# STM32U5Fx register map
File version: 1.0
CPU: CM33 r0p1, little endian, MPU, FPU, 4 interrupt priority bits
Registers are 32-bit, read-write, reset 0x0 unless marked. A register's access mark holds for its fields unless they carry their own. Offsets are from the block's base; [hi:lo] are bit positions; {n}, {i} and the like mark numbered series; 'fields as' and 'values as' point back to an identical list.

## OCTOSPIM — OCTOSPI I/O manager
Base 0x420C4000
Same registers: SEC_OCTOSPIM 0x520C4000
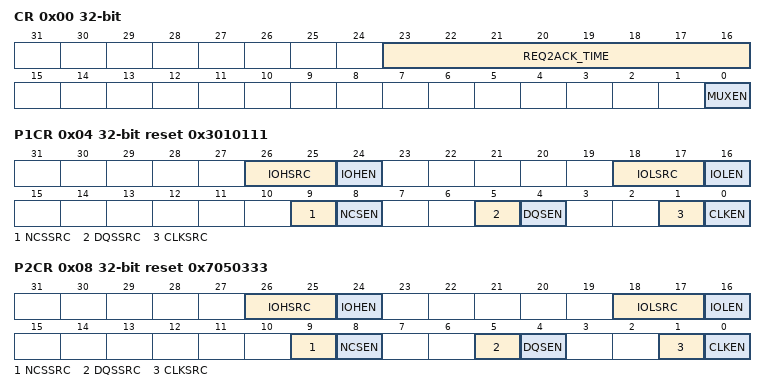
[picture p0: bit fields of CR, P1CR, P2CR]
0x00 CR — control register
  [23:16] REQ2ACK_TIME — REQ to ACK time
  [0] MUXEN — Multiplexed mode enable
0x04 P1CR reset 0x3010111 — OCTOSPI I/O manager Port 1 configuration register
  [26:25] IOHSRC — IOHSR
  [24] IOHEN
  [18:17] IOLSRC
  [16] IOLEN
  [9] NCSSRC
  [8] NCSEN
  [5] DQSSRC
  [4] DQSEN
  [1] CLKSRC
  [0] CLKEN
0x08 P2CR reset 0x7050333 — OCTOSPI I/O manager Port 2 configuration register
  fields as P1CR

## PSSI
Base 0x4202C400
Same registers: SEC_PSSI 0x5202C400
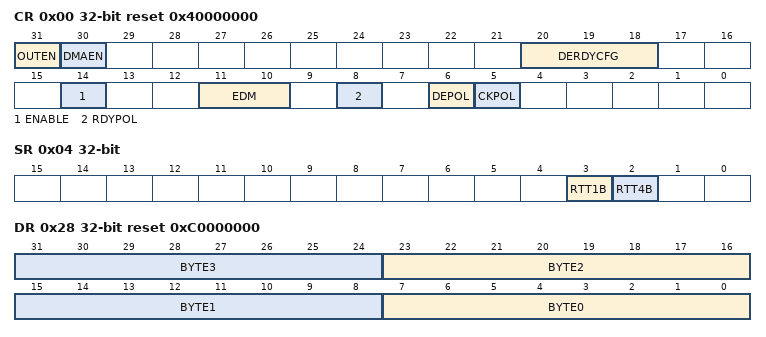
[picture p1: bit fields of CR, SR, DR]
0x00 CR reset 0x40000000 — PSSI control register
  [31] OUTEN — Data direction selection bit
  [30] DMAEN — DMA enable bit
  [20:18] DERDYCFG — Data enable and ready configuration When the PSSI_RDY function is mapped to the PSSI_DE pin (settings 101 or 111), it is still the RDYPOL bit which determines its polarity. Similarly, when the PSSI_DE function is mapped to the PSSI_RDY pin (settings 110 or 111), it is still the DEPOL bit which determines its polarity.
  [14] ENABLE — PSSI enable The contents of the FIFO are flushed when ENABLE is cleared to 0. Note: When ENABLE=1, the content of PSSI_CR must not be changed, except for the ENABLE bit itself. All configuration bits can change as soon as ENABLE changes from 0 to 1. The DMA controller and all PSSI configuration registers must be programmed correctly before setting the ENABLE bit to 1. The ENABLE bit and the DCMI ENABLE bit (bit 15 of DCMI_CR) must not be set to 1 at the same time.
  [11:10] EDM — Extended data mode
  [8] RDYPOL — Ready (PSSI_RDY) polarity This bit indicates the level on the PSSI_RDY pin when the data are not valid on the parallel interface.
  [6] DEPOL — Data enable (PSSI_DE) polarity This bit indicates the level on the PSSI_DE pin when the data are not valid on the parallel interface.
  [5] CKPOL — Parallel data clock polarity This bit configures the capture edge of the parallel clock or the edge used for driving outputs, depending on OUTEN.
0x04 SR ro — PSSI status register
  [3] RTT1B, [2] RTT4B
0x08 RIS ro — PSSI raw interrupt status register
  [1] OVR_RIS
0x0C IER — PSSI interrupt enable register
  [1] OVR_IE
0x10 MIS ro — PSSI masked interrupt status register
  [1] OVR_MIS
0x14 ICR wo — PSSI interrupt clear register
  [1] OVR_ISC
0x28 DR reset 0xC0000000 — PSSI data register
  [8n+7:8n] BYTE{n} (n=0..3) — Data byte {n}

## RNG — Random number generator
Base 0x420C0800
Same registers: SEC_RNG 0x520C0800
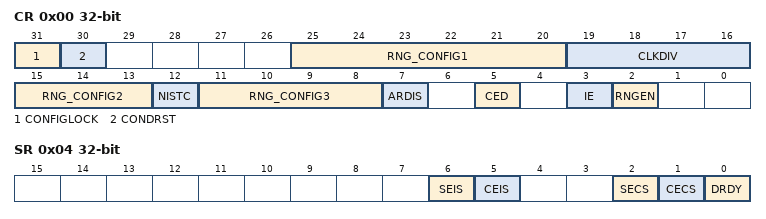
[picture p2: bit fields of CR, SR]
0x00 CR — control register
  [31] CONFIGLOCK — RNG Config Lock
  [30] CONDRST — Conditioning soft reset
  [25:20] RNG_CONFIG1 — RNG configuration 1
  [19:16] CLKDIV — Clock divider factor
  [15:13] RNG_CONFIG2 — RNG configuration 2
  [12] NISTC — Non NIST compliant
  [11:8] RNG_CONFIG3 — RNG configuration 3
  [7] ARDIS — Auto reset disable
  [5] CED — Clock error detection
  [3] IE — Interrupt Enable
  [2] RNGEN — True random number generator enable
0x04 SR access per field — status register
  [6] SEIS rw — Seed error interrupt status
  [5] CEIS rw — Clock error interrupt status
  [2] SECS ro — Seed error current status
  [1] CECS ro — Clock error current status
  [0] DRDY ro — Data ready
0x08 DR ro — data register
  [31:0] RNDATA — Random data
0x10 HTCR reset 0x6274 — health test control register
  [31:0] HTCFG — health test configuration

## SPI1 — Serial peripheral interface
Base 0x40013000
Same registers: SPI2 0x40003800, SPI3 0x46002000, SEC_SPI2 0x50003800, SEC_SPI1 0x50013000, SEC_SPI3 0x56002000
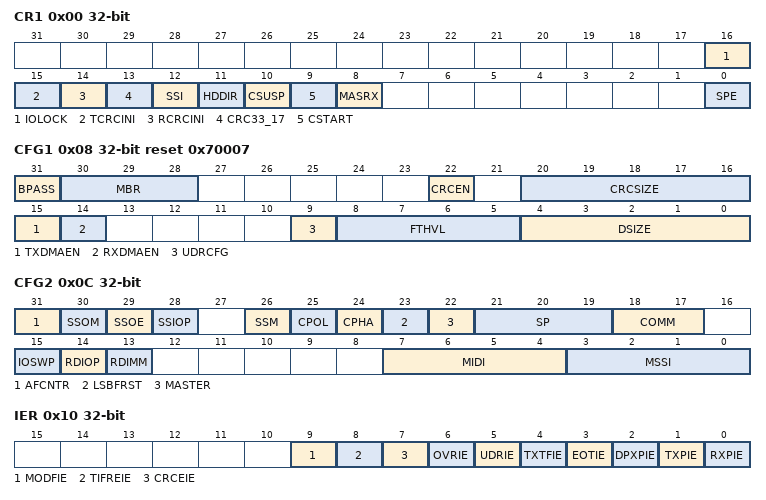
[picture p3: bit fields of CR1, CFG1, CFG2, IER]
0x00 CR1 access per field — control register 1
  [16] IOLOCK rw, [15] TCRCINI rw, [14] RCRCINI rw, [13] CRC33_17 rw, [12] SSI rw, [11] HDDIR rw, [10] CSUSP wo, [9] CSTART rw, [8] MASRX rw, [0] SPE rw
0x04 CR2 — control register 2
  [15:0] TSIZE
0x08 CFG1 reset 0x70007 — configuration register 1
  [31] BPASS
  [30:28] MBR — Master baud rate
  [22] CRCEN — Hardware CRC computation enable
  [20:16] CRCSIZE — Length of CRC frame to be transacted and compared
  [15] TXDMAEN — Tx DMA stream enable
  [14] RXDMAEN — Rx DMA stream enable
  [9] UDRCFG — Behavior of slave transmitter at underrun condition
  [8:5] FTHVL — threshold level
  [4:0] DSIZE — Number of bits in at single SPI data frame
0x0C CFG2 — configuration register 2
  [31] AFCNTR — Alternate function GPIOs control
  [30] SSOM — SS output management in master mode
  [29] SSOE — SS output enable
  [28] SSIOP — SS input/output polarity
  [26] SSM — Software management of SS signal input
  [25] CPOL — Clock polarity
  [24] CPHA — Clock phase
  [23] LSBFRST — Data frame format
  [22] MASTER — SPI Master
  [21:19] SP — Serial Protocol
  [18:17] COMM — SPI Communication Mode
  [15] IOSWP — Swap functionality of MISO and MOSI pins
  [14] RDIOP
  [13] RDIMM
  [7:4] MIDI — Master Inter-Data Idleness
  [3:0] MSSI — Master SS Idleness
0x10 IER — Interrupt Enable Register
  [9] MODFIE — Mode Fault interrupt enable
  [8] TIFREIE — TIFRE interrupt enable
  [7] CRCEIE — CRC Interrupt enable
  [6] OVRIE — OVR interrupt enable
  [5] UDRIE — UDR interrupt enable
  [4] TXTFIE — TXTFIE interrupt enable
  [3] EOTIE — EOT, SUSP and TXC interrupt enable
  [2] DPXPIE — DXP interrupt enabled
  [1] TXPIE — TXP interrupt enable
  [0] RXPIE — RXP Interrupt Enable
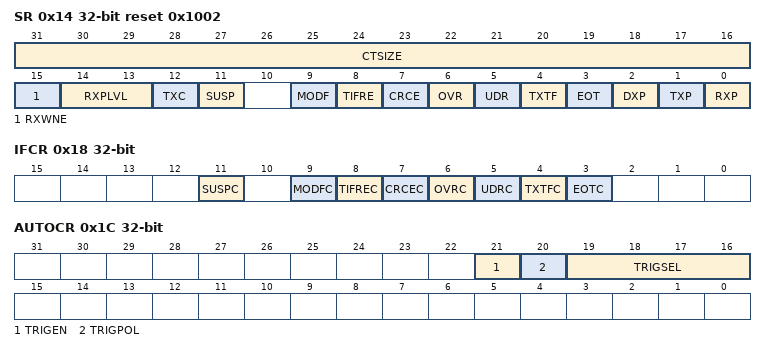
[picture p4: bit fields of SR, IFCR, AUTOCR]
0x14 SR ro reset 0x1002 — Status Register
  [31:16] CTSIZE — Number of data frames remaining in current TSIZE session
  [15] RXWNE — RxFIFO Word Not Empty
  [14:13] RXPLVL — RxFIFO Packing LeVeL
  [12] TXC — TxFIFO transmission complete
  [11] SUSP — SUSPend
  [9] MODF — Mode Fault
  [8] TIFRE — TI frame format error
  [7] CRCE — CRC Error
  [6] OVR — Overrun
  [5] UDR — Underrun at slave transmission mode
  [4] TXTF — Transmission Transfer Filled
  [3] EOT — End Of Transfer
  [2] DXP — Duplex Packet
  [1] TXP — Tx-Packet space available
  [0] RXP — Rx-Packet available
0x18 IFCR wo — Interrupt/Status Flags Clear Register
  [11] SUSPC — SUSPend flag clear
  [9] MODFC — Mode Fault flag clear
  [8] TIFREC — TI frame format error flag clear
  [7] CRCEC — CRC Error flag clear
  [6] OVRC — Overrun flag clear
  [5] UDRC — Underrun flag clear
  [4] TXTFC — Transmission Transfer Filled flag clear
  [3] EOTC — End Of Transfer flag clear
0x1C AUTOCR — SPI autonomous mode control register
  [21] TRIGEN, [20] TRIGPOL, [19:16] TRIGSEL
0x20 TXDR wo — Transmit Data Register
  [31:0] TXDR — Transmit data register
0x30 RXDR ro — Receive Data Register
  [31:0] RXDR — Receive data register
0x40 CRCPOLY reset 0x107 — Polynomial Register
  [31:0] CRCPOLY — CRC polynomial register
0x44 TXCRC ro — Transmitter CRC Register
  [31:0] TXCRC — CRC register for transmitter
0x48 RXCRC ro — Receiver CRC Register
  [31:0] RXCRC — CRC register for receiver
0x4C UDRDR — Underrun Data Register
  [31:0] UDRDR — Data at slave underrun condition
